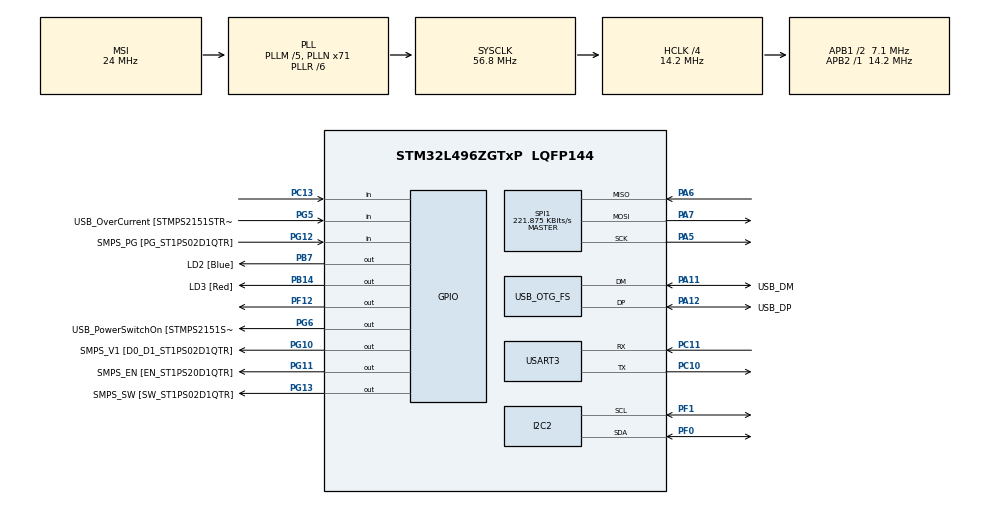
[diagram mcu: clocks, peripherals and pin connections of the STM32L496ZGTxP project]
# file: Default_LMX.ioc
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I2C2.Timing=0x00101A26
Mcu.Family=STM32L4
Mcu.Name=STM32L496ZGTxP
Mcu.Package=LQFP144
NVIC.OTG_FS_IRQn=true\:0\:0\:false\:false\:true\:true\:true\:true
NVIC.PriorityGroup=NVIC_PRIORITYGROUP_4
PA10.GPIO_Label=USB_ID
PA10.Signal=USB_OTG_FS_ID
PA11.GPIO_Label=USB_DM
PA11.Mode=Host_Only
PA11.Signal=USB_OTG_FS_DM
PA12.GPIO_Label=USB_DP
PA12.Mode=Host_Only
PA12.Signal=USB_OTG_FS_DP
PA13\ (JTMS/SWDIO).GPIO_Label=TMS
PA13\ (JTMS/SWDIO).Mode=Trace_Asynchronous_SW
PA13\ (JTMS/SWDIO).Signal=SYS_JTMS-SWDIO
PA14\ (JTCK/SWCLK).GPIO_Label=TCK
PA14\ (JTCK/SWCLK).Mode=Trace_Asynchronous_SW
PA14\ (JTCK/SWCLK).Signal=SYS_JTCK-SWCLK
PA5.Mode=Full_Duplex_Master
PA5.Signal=SPI1_SCK
PA6.Mode=Full_Duplex_Master
PA6.Signal=SPI1_MISO
PA7.Mode=Full_Duplex_Master
PA7.Signal=SPI1_MOSI
PA8.GPIO_Label=USB_SOF [TP1]
PA8.Signal=USB_OTG_FS_SOF
PA9.GPIO_Label=USB_VBUS
PA9.Signal=USB_OTG_FS_VBUS
PB14.GPIO_Label=LD3 [Red]
PB14.Signal=GPIO_Output
PB3\ (JTDO/TRACESWO).GPIO_Label=SWO
PB3\ (JTDO/TRACESWO).Mode=Trace_Asynchronous_SW
PB3\ (JTDO/TRACESWO).Signal=SYS_JTDO-SWO
PB7.GPIO_Label=LD2 [Blue]
PB7.Signal=GPIO_Output
PC10.Mode=Asynchronous
PC10.Signal=USART3_TX
PC11.Mode=Asynchronous
PC11.Signal=USART3_RX
PC13.Signal=GPIO_Input
PC14-OSC32_IN\ (PC14).Mode=LSE-External-Oscillator
PC14-OSC32_IN\ (PC14).Signal=RCC_OSC32_IN
PC15-OSC32_OUT\ (PC15).Mode=LSE-External-Oscillator
PC15-OSC32_OUT\ (PC15).Signal=RCC_OSC32_OUT
PF0.Mode=I2C
PF0.Signal=I2C2_SDA
PF1.Mode=I2C
PF1.Signal=I2C2_SCL
PF12.Signal=GPIO_Output
PG10.GPIO_Label=SMPS_V1 [D0_D1_ST1PS02D1QTR]
PG10.Signal=GPIO_Output
PG11.GPIO_Label=SMPS_EN [EN_ST1PS20D1QTR]
PG11.Signal=GPIO_Output
PG12.GPIO_Label=SMPS_PG [PG_ST1PS02D1QTR]
PG12.Signal=GPIO_Input
PG13.GPIO_Label=SMPS_SW [SW_ST1PS02D1QTR]
PG13.Signal=GPIO_Output
PG5.GPIO_Label=USB_OverCurrent [STMPS2151STR_FAULT]
PG5.Signal=GPIO_Input
PG6.GPIO_Label=USB_PowerSwitchOn [STMPS2151STR_EN]
PG6.Signal=GPIO_Output
PG7.GPIO_Label=STLK_RX [STM32F103CBT6_PA3]
PG7.Signal=LPUART1_TX
PG8.GPIO_Label=STLK_TX [STM32F103CBT6_PA2]
PG8.Signal=LPUART1_RX
PH0-OSC_IN\ (PH0).GPIO_Label=MCO
PH0-OSC_IN\ (PH0).Signal=RCC_OSC_IN
PH1-OSC_OUT\ (PH1).Signal=RCC_OSC_OUT
ProjectManager.HeapSize=0x200
ProjectManager.StackSize=0x400
ProjectManager.TargetToolchain=STM32CubeIDE
RCC.48MHZClocksFreq_Value=24000000
RCC.ADCFreq_Value=48000000
RCC.AHBCLKDivider=RCC_SYSCLK_DIV4
RCC.AHBFreq_Value=14200000
RCC.APB1CLKDivider=RCC_HCLK_DIV2
RCC.APB1Freq_Value=7100000
RCC.APB1TimFreq_Value=14200000
RCC.APB2Freq_Value=14200000
RCC.APB2TimFreq_Value=14200000
RCC.CortexFreq_Value=14200000
RCC.HCLKFreq_Value=14200000
RCC.HSE_VALUE=8000000
RCC.HSI48_VALUE=48000000
RCC.HSI_VALUE=16000000
RCC.MSIClockRange=RCC_MSIRANGE_9
RCC.MSI_VALUE=24000000
RCC.PLLM=5
RCC.PLLMUL=RCC_PLL_MUL9
RCC.PLLN=71
RCC.PLLR=RCC_PLLR_DIV6
RCC.PLLSAI1N=20
RCC.PRESCALERUSB=RCC_USBCLKSOURCE_PLL_DIV1_5
RCC.SYSCLKFreq_VALUE=56800000
RCC.SYSCLKSource=RCC_SYSCLKSOURCE_PLLCLK
RCC.SYSCLKSourceVirtual=RCC_SYSCLKSOURCE_PLLCLK
RCC.USBFreq_Value=48000000
RCC.VCOOutputFreq_Value=340800000
SPI1.BaudRatePrescaler=SPI_BAUDRATEPRESCALER_64
SPI1.CalculateBaudRate=221.875 KBits/s
SPI1.DataSize=SPI_DATASIZE_8BIT
SPI1.Direction=SPI_DIRECTION_2LINES
SPI1.Mode=SPI_MODE_MASTER
SPI1.VirtualType=VM_MASTER
USART3.VirtualMode-Asynchronous=VM_ASYNC
USB_HOST.BSP.number=1
USB_HOST.USBH_HandleTypeDef=hUsbHostFS
USB_HOST.VirtualModeFS=Audio
USB_HOST0.BSP.STBoard=false
USB_HOST0.BSP.api=UnknownBspDriver
USB_HOST0.BSP.instance=PG6
USB_HOST0.BSP.ip=GPIO
USB_HOST0.BSP.mode=Output
USB_HOST0.BSP.name=Drive_VBUS_FS
USB_HOST0.BSP.solution=PG6
USB_OTG_FS.VirtualMode=Host_Only
USB_OTG_FS.phy_itface=HCD_PHY_EMBEDDED
VP_USB_HOST_VS_USB_HOST_AUDIO_FS.Mode=AUDIO_FS
board=NUCLEO-L496ZG-P

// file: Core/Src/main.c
/* USER CODE BEGIN Header */
/**
  ******************************************************************************
  * @file           : main.c
  * @brief          : Main program body
  * @Author         : Ronak Sharma
  ******************************************************************************
  * @attention
  *
  * Copyright (c) 2023 STMicroelectronics.
  * All rights reserved.
  *
  * This software is licensed under terms that can be found in the LICENSE file
  * in the root directory of this software component.
  * If no LICENSE file comes with this software, it is provided AS-IS.
  *
  ******************************************************************************
  */
/* USER CODE END Header */
#include "main.h"
#include "usb_host.h"

/* USER CODE BEGIN Includes */
#include<stdio.h>
#include<string.h>
/* USER CODE END Includes */

I2C_HandleTypeDef hi2c2;

SPI_HandleTypeDef hspi1;

UART_HandleTypeDef huart3;

void SystemClock_Config(void);
static void MX_GPIO_Init(void);
static void MX_SPI1_Init(void);
static void MX_USART3_UART_Init(void);
void MX_USB_HOST_Process(void);

/* USER CODE BEGIN PFP */
void Default_LMX_setup(void);
void LMX_93_75MHz_setup(void);//function for 93.75MHz default setting
/* USER CODE END PFP */

int main(void)
{
  /* USER CODE BEGIN 1 */
uint8_t S_Buf[250]="Application is Running\n";
  /* USER CODE END 1 */

  /* MCU Configuration--------------------------------------------------------*/

  /* Reset of all peripherals, Initializes the Flash interface and the Systick. */
  HAL_Init();

  /* Configure the system clock */
  SystemClock_Config();

  /* Initialize all configured peripherals */
  MX_GPIO_Init();
  MX_USB_HOST_Init();
  MX_I2C2_Init();
  MX_SPI1_Init();
  MX_USART3_UART_Init();
  /* USER CODE BEGIN 2 */

  HAL_UART_Transmit(&huart3, S_Buf, strlen((char*)S_Buf),1000);
  //CS pin, keep it high
  HAL_GPIO_WritePin(GPIOF, GPIO_PIN_12, GPIO_PIN_SET);

  Default_LMX_setup();

  /* USER CODE END 2 */

  /* Infinite loop */
  /* USER CODE BEGIN WHILE */
  while (1)
  {
    while(! HAL_GPIO_ReadPin(GPIOC, GPIO_PIN_13));
    LMX_93_75MHz_setup();

  }
  /* USER CODE END 3 */
}

/*
 * @brief Default function for LMX setup
 * @Param None
 * @retval None
 */
void Default_LMX_setup(void){

	int R[123]={0x7A0000, 0x790000, 0x780000, 0x770000, 0x760000, 0x750000, 0x740000, 0x730000, 0x720000, 0x710000,
				0x70FFFF, 0x6F0000, 0x6E001F, 0x6D0000, 0x6C0000, 0x6B0000, 0x6A0000, 0x69000A, 0x680014, 0x670014,
				0x660028, 0x6503E8, 0x640533, 0x6319B9, 0x621C80, 0x610000, 0x6017F8, 0x5F0000, 0x5E0000, 0x5D1000,
				0x5C0000, 0x5B0000, 0x5A0000, 0x590000, 0x5803FF, 0x57FF00, 0x560040, 0x550000, 0x540040, 0x530F00,
				0x520000, 0x510000, 0x5001C0, 0x4F010E, 0x4E0002, 0x4D0608, 0x4C0000, 0x4B0000, 0x4A0000, 0x490000,
				0x480000, 0x470000, 0x46000E, 0x450011, 0x440000, 0x431000, 0x42003F, 0x410000, 0x400080, 0x3FC350,
				0x3E0000, 0x3D03E8, 0x3C01F4, 0x3B1388, 0x3A0000, 0x390001, 0x380001, 0x370002, 0x360000, 0x350000,
				0x340000, 0x33203F, 0x320080, 0x310000, 0x304180, 0x2F0300, 0x2E0300, 0x2DD70A, 0x2C40A3, 0x2B0065,
				0x2A0000, 0x290000, 0x280000, 0x270190, 0x260000, 0x250500, 0x24001C, 0x233180, 0x220010, 0x210000,
				0x201B81, 0x1F0401, 0x1EB18C, 0x1D318C, 0x1C0639, 0x1B8001, 0x1A0DB0, 0x190624, 0x180E34, 0x171102,
				0x16E2BF, 0x151C64, 0x14272C, 0x132120, 0x120000, 0x1115C0, 0x101712, 0x0F2001, 0x0E3001, 0x0D0038,
				0x0C0408, 0x0B0602, 0x0A0000, 0x090005, 0x08C802, 0x070000, 0x060A43, 0x050032, 0x044204, 0x030041,
				0x0281F4, 0x01D7A0, 0x006470};

	uint8_t S_Buf[50];
	uint8_t Adr;
	uint8_t data[2];

	Adr=0x00;
	data[0]=0x00;
	data[1]=0x00;

	for(int8_t i=0;i<=122;i++)
	{
		//Bit wise operations to get the address and data to be sent
		Adr = (R[i] & 0xFF0000)>>16;
		data[0]=(R[i] & 0xFF00)>>8;
		data[1]=(R[i] & 0xFF);

		sprintf((char *)S_Buf,"Address and Data : 0x%X 0x%X 0x%X \n",Adr,data[0],data[1]);
		HAL_UART_Transmit(&huart3, S_Buf, strlen((char*)S_Buf),1000);

		HAL_GPIO_WritePin(GPIOF, GPIO_PIN_12, GPIO_PIN_RESET);//CS Pin low
		HAL_SPI_Transmit(&hspi1, &Adr, 1, 1000); //Transmit address
		HAL_SPI_Transmit(&hspi1, &data[0], 2, 1000); //Transmit data
		HAL_GPIO_WritePin(GPIOF, GPIO_PIN_12, GPIO_PIN_SET); // CS pin High
	}

   strcpy((char *)S_Buf,"Address and Data sent to registers \n");
   HAL_UART_Transmit(&huart3, S_Buf, strlen((char*)S_Buf),1000);

}
/*
 * @brief Default function for 93.75MHz frequency setup
 * @Param None
 * @retval None
 */
void LMX_93_75MHz_setup(void){

	//Register values for 93.75MHz Frequency
	int R[123]={0x006470,   0x0157A0,   0x0281F4,   0x030041,   0x044204,   0x050032,   0x060A43,   0x070000,   0x08C802,   0x090005,
		    0x0A0000,   0x0B0612,   0x0C0408,   0x0D0038,   0x0E3001,   0x0F2001,   0x10171C,   0x1115C0,   0x120000,	0x132120,
		    0x14272C,	0x151C64,   0x16E2BF,	0x171102,   0x180E34,	0x190624,   0x1A0DB0,	0x1B8001,   0x1C0639,	0x1D318C,
		    0x1EB18C,	0x1F0401,   0x201141,	0x210000,   0x220010,	0x233100,   0x24001E,	0x250500,   0x260000,	0x270190,
		    0x280000,	0x290000,   0x2A0000,	0x2B0000,   0x2C0000,	0x2D0000,   0x2E0300,	0x2F0300,   0x304180,	0x310000,
		    0x320080,	0x33203F,   0x340000,	0x350000,   0x360000,	0x370002,   0x380001,	0x390001,   0x3A0000,	0x3B1388,
		    0x3C01F4,	0x3D03E8,   0x3E0000,	0x3FC350,   0x400080,	0x410000,   0x42003F,	0x431000,   0x440020,	0x450011,
		    0x46000E,	0x478801,   0x480008,	0x499D7D,   0x4A88C5,	0x4B00FA,   0x4C0000,	0x4D0608,   0x4E0000,	0x4F0110,
		    0x5001C0,	0x510000,   0x520000,	0x530F00,   0x540040,	0x550000,   0x560040,	0x57FF00,   0x5803FF,	0x590000,
		    0x5A0000,	0x5B0000,   0x5C0000,	0x5D1000,   0x5E0000,	0x5F0000,   0x6017F8,	0x610000,   0x621C80,	0x6319B9,
		    0x640533,	0x6503E8,   0x660028,	0x670014,   0x680014,	0x69000A,   0x6A0000,	0x6B0000,   0x6C0000,	0x6D0000,
		    0x6E001F,	0x6F0000,   0x70FFFF,	0x71C000,   0x720000,	0x730000,   0x74FF00,	0x750000,   0x760000,	0x770009,
		    0x780000,	0x790000,   0x7A0000};
	uint8_t S_Buf[50];
	uint8_t Adr;
	uint8_t data[2];

	Adr=0x00;
	data[0]=0x00;
	data[1]=0x00;

    for(int8_t i=122;i>=0;i--)
    {
    	//Bit wise operations to get the address and data to be sent
		Adr = (R[i] & 0xFF0000)>>16;
		data[0]=(R[i] & 0xFF00)>>8;
		data[1]=(R[i] & 0xFF);

		sprintf((char *)S_Buf,"Address and Data : 0x%X 0x%X 0x%X \n",Adr,data[0],data[1]);
		HAL_UART_Transmit(&huart3, S_Buf, strlen((char*)S_Buf),1000);

		HAL_GPIO_WritePin(GPIOF, GPIO_PIN_12, GPIO_PIN_RESET);//CS Pin low
		HAL_SPI_Transmit(&hspi1, &Adr, 1, 1000); //Transmit address
		HAL_SPI_Transmit(&hspi1, &data[0], 2, 1000); //Transmit data
		HAL_GPIO_WritePin(GPIOF, GPIO_PIN_12, GPIO_PIN_SET); // CS pin High
    }

   strcpy((char *)S_Buf,"Address and Data sent to registers \n");
   HAL_UART_Transmit(&huart3, S_Buf, strlen((char*)S_Buf),1000);

}

void SystemClock_Config(void)
{
  RCC_OscInitTypeDef RCC_OscInitStruct = {0};
  RCC_ClkInitTypeDef RCC_ClkInitStruct = {0};

  /** Configure the main internal regulator output voltage
  */
  if (HAL_PWREx_ControlVoltageScaling(PWR_REGULATOR_VOLTAGE_SCALE1) != HAL_OK)
  {
    Error_Handler();
  }

  /** Configure LSE Drive Capability
  */
  HAL_PWR_EnableBkUpAccess();
  __HAL_RCC_LSEDRIVE_CONFIG(RCC_LSEDRIVE_LOW);

  /** Initializes the RCC Oscillators according to the specified parameters
  * in the RCC_OscInitTypeDef structure.
  */
  RCC_OscInitStruct.OscillatorType = RCC_OSCILLATORTYPE_LSE|RCC_OSCILLATORTYPE_MSI;
  RCC_OscInitStruct.LSEState = RCC_LSE_ON;
  RCC_OscInitStruct.MSIState = RCC_MSI_ON;
  RCC_OscInitStruct.MSICalibrationValue = 0;
  RCC_OscInitStruct.MSIClockRange = RCC_MSIRANGE_9;
  RCC_OscInitStruct.PLL.PLLState = RCC_PLL_ON;
  RCC_OscInitStruct.PLL.PLLSource = RCC_PLLSOURCE_MSI;
  RCC_OscInitStruct.PLL.PLLM = 5;
  RCC_OscInitStruct.PLL.PLLN = 71;
  RCC_OscInitStruct.PLL.PLLP = RCC_PLLP_DIV2;
  RCC_OscInitStruct.PLL.PLLQ = RCC_PLLQ_DIV2;
  RCC_OscInitStruct.PLL.PLLR = RCC_PLLR_DIV6;
  if (HAL_RCC_OscConfig(&RCC_OscInitStruct) != HAL_OK)
  {
    Error_Handler();
  }

  /** Initializes the CPU, AHB and APB buses clocks
  */
  RCC_ClkInitStruct.ClockType = RCC_CLOCKTYPE_HCLK|RCC_CLOCKTYPE_SYSCLK
                              |RCC_CLOCKTYPE_PCLK1|RCC_CLOCKTYPE_PCLK2;
  RCC_ClkInitStruct.SYSCLKSource = RCC_SYSCLKSOURCE_PLLCLK;
  RCC_ClkInitStruct.AHBCLKDivider = RCC_SYSCLK_DIV4;
  RCC_ClkInitStruct.APB1CLKDivider = RCC_HCLK_DIV2;
  RCC_ClkInitStruct.APB2CLKDivider = RCC_HCLK_DIV1;

  if (HAL_RCC_ClockConfig(&RCC_ClkInitStruct, FLASH_LATENCY_0) != HAL_OK)
  {
    Error_Handler();
  }

  /** Enable MSI Auto calibration
  */
  HAL_RCCEx_EnableMSIPLLMode();
}

static void MX_I2C2_Init(void)
{

  hi2c2.Instance = I2C2;
  hi2c2.Init.Timing = 0x00101A26;
  hi2c2.Init.OwnAddress1 = 0;
  hi2c2.Init.AddressingMode = I2C_ADDRESSINGMODE_7BIT;
  hi2c2.Init.DualAddressMode = I2C_DUALADDRESS_DISABLE;
  hi2c2.Init.OwnAddress2 = 0;
  hi2c2.Init.OwnAddress2Masks = I2C_OA2_NOMASK;
  hi2c2.Init.GeneralCallMode = I2C_GENERALCALL_DISABLE;
  hi2c2.Init.NoStretchMode = I2C_NOSTRETCH_DISABLE;
  if (HAL_I2C_Init(&hi2c2) != HAL_OK)
  {
    Error_Handler();
  }

  /** Configure Analogue filter
  */
  if (HAL_I2CEx_ConfigAnalogFilter(&hi2c2, I2C_ANALOGFILTER_ENABLE) != HAL_OK)
  {
    Error_Handler();
  }

  /** Configure Digital filter
  */
  if (HAL_I2CEx_ConfigDigitalFilter(&hi2c2, 0) != HAL_OK)
  {
    Error_Handler();
  }

}

static void MX_SPI1_Init(void)
{

  /* SPI1 parameter configuration*/
  hspi1.Instance = SPI1;
  hspi1.Init.Mode = SPI_MODE_MASTER;
  hspi1.Init.Direction = SPI_DIRECTION_2LINES;
  hspi1.Init.DataSize = SPI_DATASIZE_8BIT;
  hspi1.Init.CLKPolarity = SPI_POLARITY_LOW;
  hspi1.Init.CLKPhase = SPI_PHASE_1EDGE;
  hspi1.Init.NSS = SPI_NSS_SOFT;
  hspi1.Init.BaudRatePrescaler = SPI_BAUDRATEPRESCALER_64;
  hspi1.Init.FirstBit = SPI_FIRSTBIT_MSB;
  hspi1.Init.TIMode = SPI_TIMODE_DISABLE;
  hspi1.Init.CRCCalculation = SPI_CRCCALCULATION_DISABLE;
  hspi1.Init.CRCPolynomial = 7;
  hspi1.Init.CRCLength = SPI_CRC_LENGTH_DATASIZE;
  hspi1.Init.NSSPMode = SPI_NSS_PULSE_ENABLE;
  if (HAL_SPI_Init(&hspi1) != HAL_OK)
  {
    Error_Handler();
  }

}

static void MX_USART3_UART_Init(void)
{

  huart3.Instance = USART3;
  huart3.Init.BaudRate = 115200;
  huart3.Init.WordLength = UART_WORDLENGTH_8B;
  huart3.Init.StopBits = UART_STOPBITS_1;
  huart3.Init.Parity = UART_PARITY_NONE;
  huart3.Init.Mode = UART_MODE_TX_RX;
  huart3.Init.HwFlowCtl = UART_HWCONTROL_NONE;
  huart3.Init.OverSampling = UART_OVERSAMPLING_16;
  huart3.Init.OneBitSampling = UART_ONE_BIT_SAMPLE_DISABLE;
  huart3.AdvancedInit.AdvFeatureInit = UART_ADVFEATURE_NO_INIT;
  if (HAL_UART_Init(&huart3) != HAL_OK)
  {
    Error_Handler();
  }

}

static void MX_GPIO_Init(void)
{
  GPIO_InitTypeDef GPIO_InitStruct = {0};

  /* GPIO Ports Clock Enable */
  __HAL_RCC_GPIOC_CLK_ENABLE();
  __HAL_RCC_GPIOF_CLK_ENABLE();
  __HAL_RCC_GPIOH_CLK_ENABLE();
  __HAL_RCC_GPIOA_CLK_ENABLE();
  __HAL_RCC_GPIOB_CLK_ENABLE();
  __HAL_RCC_GPIOG_CLK_ENABLE();
  HAL_PWREx_EnableVddIO2();

  /*Configure GPIO pin Output Level */
  HAL_GPIO_WritePin(GPIOF, GPIO_PIN_12, GPIO_PIN_RESET);

  /*Configure GPIO pin Output Level */
  HAL_GPIO_WritePin(GPIOB, LD3_Pin|LD2_Pin, GPIO_PIN_RESET);

  /*Configure GPIO pin Output Level */
  HAL_GPIO_WritePin(GPIOG, USB_PowerSwitchOn_Pin|SMPS_V1_Pin|SMPS_EN_Pin|SMPS_SW_Pin, GPIO_PIN_RESET);

  /*Configure GPIO pin : PC13 */
  GPIO_InitStruct.Pin = GPIO_PIN_13;
  GPIO_InitStruct.Mode = GPIO_MODE_INPUT;
  GPIO_InitStruct.Pull = GPIO_NOPULL;
  HAL_GPIO_Init(GPIOC, &GPIO_InitStruct);

  /*Configure GPIO pin : PF12 */
  GPIO_InitStruct.Pin = GPIO_PIN_12;
  GPIO_InitStruct.Mode = GPIO_MODE_OUTPUT_PP;
  GPIO_InitStruct.Pull = GPIO_NOPULL;
  GPIO_InitStruct.Speed = GPIO_SPEED_FREQ_LOW;
  HAL_GPIO_Init(GPIOF, &GPIO_InitStruct);

  /*Configure GPIO pins : LD3_Pin LD2_Pin */
  GPIO_InitStruct.Pin = LD3_Pin|LD2_Pin;
  GPIO_InitStruct.Mode = GPIO_MODE_OUTPUT_PP;
  GPIO_InitStruct.Pull = GPIO_NOPULL;
  GPIO_InitStruct.Speed = GPIO_SPEED_FREQ_LOW;
  HAL_GPIO_Init(GPIOB, &GPIO_InitStruct);

  /*Configure GPIO pins : USB_OverCurrent_Pin SMPS_PG_Pin */
  GPIO_InitStruct.Pin = USB_OverCurrent_Pin|SMPS_PG_Pin;
  GPIO_InitStruct.Mode = GPIO_MODE_INPUT;
  GPIO_InitStruct.Pull = GPIO_NOPULL;
  HAL_GPIO_Init(GPIOG, &GPIO_InitStruct);

  /*Configure GPIO pins : USB_PowerSwitchOn_Pin SMPS_V1_Pin SMPS_EN_Pin SMPS_SW_Pin */
  GPIO_InitStruct.Pin = USB_PowerSwitchOn_Pin|SMPS_V1_Pin|SMPS_EN_Pin|SMPS_SW_Pin;
  GPIO_InitStruct.Mode = GPIO_MODE_OUTPUT_PP;
  GPIO_InitStruct.Pull = GPIO_NOPULL;
  GPIO_InitStruct.Speed = GPIO_SPEED_FREQ_LOW;
  HAL_GPIO_Init(GPIOG, &GPIO_InitStruct);

  /*Configure GPIO pins : STLK_RX_Pin STLK_TX_Pin */
  GPIO_InitStruct.Pin = STLK_RX_Pin|STLK_TX_Pin;
  GPIO_InitStruct.Mode = GPIO_MODE_AF_PP;
  GPIO_InitStruct.Pull = GPIO_NOPULL;
  GPIO_InitStruct.Speed = GPIO_SPEED_FREQ_VERY_HIGH;
  GPIO_InitStruct.Alternate = GPIO_AF8_LPUART1;
  HAL_GPIO_Init(GPIOG, &GPIO_InitStruct);

}

void Error_Handler(void)
{
  __disable_irq();
  while (1)
  {
  }
}
